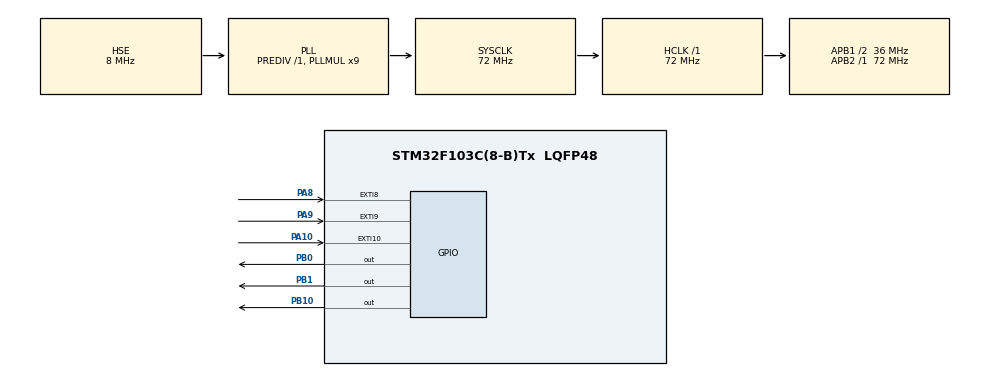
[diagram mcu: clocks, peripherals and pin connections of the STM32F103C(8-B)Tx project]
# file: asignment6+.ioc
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FREERTOS.Tasks01=LED1,24,128,StartLED1,Default,NULL,Dynamic,NULL,NULL;LED2,8,128,StartLED2,Default,NULL,Dynamic,NULL,NULL;LED3,8,128,StartLED3,Default,NULL,Dynamic,NULL,NULL
Mcu.Family=STM32F1
Mcu.Name=STM32F103C(8-B)Tx
Mcu.Package=LQFP48
NVIC.EXTI15_10_IRQn=true\:5\:0\:false\:false\:true\:true\:true\:true\:true
NVIC.EXTI9_5_IRQn=true\:5\:0\:false\:false\:true\:true\:true\:true\:true
NVIC.PriorityGroup=NVIC_PRIORITYGROUP_4
PA10.GPIO_ModeDefaultEXTI=GPIO_MODE_IT_FALLING
PA10.GPIO_PuPd=GPIO_PULLUP
PA10.Signal=GPXTI10
PA13.Mode=Serial_Wire
PA13.Signal=SYS_JTMS-SWDIO
PA14.Mode=Serial_Wire
PA14.Signal=SYS_JTCK-SWCLK
PA8.GPIO_ModeDefaultEXTI=GPIO_MODE_IT_FALLING
PA8.GPIO_PuPd=GPIO_PULLUP
PA8.Signal=GPXTI8
PA9.GPIO_ModeDefaultEXTI=GPIO_MODE_IT_FALLING
PA9.GPIO_PuPd=GPIO_PULLUP
PA9.Signal=GPXTI9
PB0.GPIO_PuPd=GPIO_PULLUP
PB0.Signal=GPIO_Output
PB1.GPIO_PuPd=GPIO_PULLUP
PB1.Signal=GPIO_Output
PB10.GPIO_PuPd=GPIO_PULLUP
PB10.Signal=GPIO_Output
PD0-OSC_IN.Mode=HSE-External-Oscillator
PD0-OSC_IN.Signal=RCC_OSC_IN
PD1-OSC_OUT.Mode=HSE-External-Oscillator
PD1-OSC_OUT.Signal=RCC_OSC_OUT
ProjectManager.HeapSize=0x200
ProjectManager.StackSize=0x400
ProjectManager.TargetToolchain=Makefile
RCC.AHBFreq_Value=72000000
RCC.APB1CLKDivider=RCC_HCLK_DIV2
RCC.APB1Freq_Value=36000000
RCC.APB1TimFreq_Value=72000000
RCC.APB2Freq_Value=72000000
RCC.APB2TimFreq_Value=72000000
RCC.HCLKFreq_Value=72000000
RCC.PLLMUL=RCC_PLL_MUL9
RCC.PLLSourceVirtual=RCC_PLLSOURCE_HSE
RCC.SYSCLKFreq_VALUE=72000000
RCC.SYSCLKSource=RCC_SYSCLKSOURCE_PLLCLK
RCC.USBFreq_Value=72000000
VP_FREERTOS_VS_CMSIS_V2.Mode=CMSIS_V2
board=custom

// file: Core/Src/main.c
/* USER CODE BEGIN Header */
/**
  ******************************************************************************
  * @file           : main.c
  * @brief          : Main program body
  ******************************************************************************
  * @attention
  *
  * Copyright (c) 2026 STMicroelectronics.
  * All rights reserved.
  *
  * This software is licensed under terms that can be found in the LICENSE file
  * in the root directory of this software component.
  * If no LICENSE file comes with this software, it is provided AS-IS.
  *
  ******************************************************************************
  */
/* USER CODE END Header */
#include "main.h"
#include "cmsis_os.h"
#include "gpio.h"

void SystemClock_Config(void);
void MX_FREERTOS_Init(void);

int main(void)
{

  /* MCU Configuration--------------------------------------------------------*/

  /* Reset of all peripherals, Initializes the Flash interface and the Systick. */
  HAL_Init();

  /* Configure the system clock */
  SystemClock_Config();

  /* Initialize all configured peripherals */
  MX_GPIO_Init();

  /* Init scheduler */
  osKernelInitialize();  /* Call init function for freertos objects (in cmsis_os2.c) */
  MX_FREERTOS_Init();

  /* Start scheduler */
  osKernelStart();

  /* We should never get here as control is now taken by the scheduler */

  /* Infinite loop */
  while (1)
  {

  }
}

void SystemClock_Config(void)
{
  RCC_OscInitTypeDef RCC_OscInitStruct = {0};
  RCC_ClkInitTypeDef RCC_ClkInitStruct = {0};

  /** Initializes the RCC Oscillators according to the specified parameters
  * in the RCC_OscInitTypeDef structure.
  */
  RCC_OscInitStruct.OscillatorType = RCC_OSCILLATORTYPE_HSE;
  RCC_OscInitStruct.HSEState = RCC_HSE_ON;
  RCC_OscInitStruct.HSEPredivValue = RCC_HSE_PREDIV_DIV1;
  RCC_OscInitStruct.HSIState = RCC_HSI_ON;
  RCC_OscInitStruct.PLL.PLLState = RCC_PLL_ON;
  RCC_OscInitStruct.PLL.PLLSource = RCC_PLLSOURCE_HSE;
  RCC_OscInitStruct.PLL.PLLMUL = RCC_PLL_MUL9;
  if (HAL_RCC_OscConfig(&RCC_OscInitStruct) != HAL_OK)
  {
    Error_Handler();
  }

  /** Initializes the CPU, AHB and APB buses clocks
  */
  RCC_ClkInitStruct.ClockType = RCC_CLOCKTYPE_HCLK|RCC_CLOCKTYPE_SYSCLK
                              |RCC_CLOCKTYPE_PCLK1|RCC_CLOCKTYPE_PCLK2;
  RCC_ClkInitStruct.SYSCLKSource = RCC_SYSCLKSOURCE_PLLCLK;
  RCC_ClkInitStruct.AHBCLKDivider = RCC_SYSCLK_DIV1;
  RCC_ClkInitStruct.APB1CLKDivider = RCC_HCLK_DIV2;
  RCC_ClkInitStruct.APB2CLKDivider = RCC_HCLK_DIV1;

  if (HAL_RCC_ClockConfig(&RCC_ClkInitStruct, FLASH_LATENCY_2) != HAL_OK)
  {
    Error_Handler();
  }
}

/* USER CODE BEGIN 4 */
/*void HAL_GPIO_EXTI_Callback(uint16_t GPIO_Pin){
     if(HAL_GPIO_ReadPin(GPIOA,GPIO_Pin)){
     HAL_GPIO_WritePin(GPIOA, GPIO_Pin, GPIO_PIN_RESET);
     }
     else{
     HAL_GPIO_WritePin(GPIOA, GPIO_Pin, GPIO_PIN_SET);
     }
  }*/
/* USER CODE END 4 */

void Error_Handler(void)
{
  __disable_irq();
  while (1)
  {
  }
}

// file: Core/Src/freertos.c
/* USER CODE BEGIN Header */
/**
  ******************************************************************************
  * File Name          : freertos.c
  * Description        : Code for freertos applications
  ******************************************************************************
  * @attention
  *
  * Copyright (c) 2026 STMicroelectronics.
  * All rights reserved.
  *
  * This software is licensed under terms that can be found in the LICENSE file
  * in the root directory of this software component.
  * If no LICENSE file comes with this software, it is provided AS-IS.
  *
  ******************************************************************************
  */
/* USER CODE END Header */

#include "FreeRTOS.h"
#include "task.h"
#include "main.h"
#include "cmsis_os.h"

/* Definitions for LED1 */
osThreadId_t LED1Handle;
const osThreadAttr_t LED1_attributes = {
  .name = "LED1",
  .stack_size = 128 * 4,
  .priority = (osPriority_t) osPriorityNormal,
};
/* Definitions for LED2 */
osThreadId_t LED2Handle;
const osThreadAttr_t LED2_attributes = {
  .name = "LED2",
  .stack_size = 128 * 4,
  .priority = (osPriority_t) osPriorityLow,
};
/* Definitions for LED3 */
osThreadId_t LED3Handle;
const osThreadAttr_t LED3_attributes = {
  .name = "LED3",
  .stack_size = 128 * 4,
  .priority = (osPriority_t) osPriorityLow,
};

void StartLED1(void *argument);
void StartLED2(void *argument);
void StartLED3(void *argument);

void MX_FREERTOS_Init(void); /* (MISRA C 2004 rule 8.1) */

void MX_FREERTOS_Init(void) {

  /* Create the thread(s) */
  /* creation of LED1 */
  LED1Handle = osThreadNew(StartLED1, NULL, &LED1_attributes);

  /* creation of LED2 */
  LED2Handle = osThreadNew(StartLED2, NULL, &LED2_attributes);

  /* creation of LED3 */
  LED3Handle = osThreadNew(StartLED3, NULL, &LED3_attributes);

}

void StartLED1(void *argument)
{
  /* USER CODE BEGIN StartLED1 */
  /* Infinite loop */
  for(;;)
  {
    HAL_GPIO_TogglePin(GPIOB,GPIO_PIN_0);
    osDelay(150);
  }
  /* USER CODE END StartLED1 */
}

void StartLED2(void *argument)
{
  /* USER CODE BEGIN StartLED2 */
  /* Infinite loop */
  for(;;)
  {
    HAL_GPIO_TogglePin(GPIOB,GPIO_PIN_1);
    osDelay(250);
  }
  /* USER CODE END StartLED2 */
}

void StartLED3(void *argument)
{
  /* USER CODE BEGIN StartLED3 */
  /* Infinite loop */
  for(;;)
  {
    HAL_GPIO_TogglePin(GPIOB,GPIO_PIN_10);
    osDelay(350);
  }
  /* USER CODE END StartLED3 */
}
